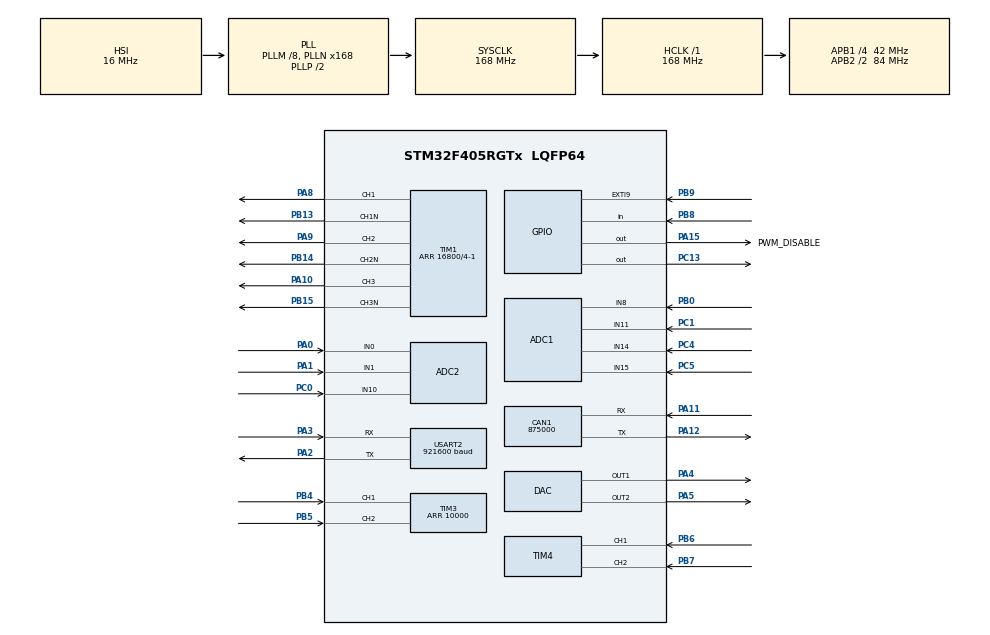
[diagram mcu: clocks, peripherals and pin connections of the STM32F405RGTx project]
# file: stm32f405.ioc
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ADC1.Channel-0\#ChannelRegularConversion=ADC_CHANNEL_14
ADC1.Channel-6\#ChannelInjectedConversion=ADC_CHANNEL_14
ADC1.Channel-7\#ChannelInjectedConversion=ADC_CHANNEL_15
ADC1.Channel-8\#ChannelInjectedConversion=ADC_CHANNEL_8
ADC1.Channel-9\#ChannelInjectedConversion=ADC_CHANNEL_11
ADC1.DMAContinuousRequests=DISABLE
ADC1.ExternalTrigInjecConv=ADC_EXTERNALTRIGINJECCONV_T1_TRGO
ADC1.InjNumberOfConversion=4
ADC1.InjectedOffset-6\#ChannelInjectedConversion=0
ADC1.InjectedOffset-7\#ChannelInjectedConversion=0
ADC1.InjectedOffset-8\#ChannelInjectedConversion=0
ADC1.InjectedOffset-9\#ChannelInjectedConversion=0
ADC1.InjectedRank-6\#ChannelInjectedConversion=1
ADC1.InjectedRank-7\#ChannelInjectedConversion=2
ADC1.InjectedRank-8\#ChannelInjectedConversion=3
ADC1.InjectedRank-9\#ChannelInjectedConversion=4
ADC1.NbrOfConversion=1
ADC1.NbrOfConversionFlag=1
ADC1.Rank-0\#ChannelRegularConversion=1
ADC1.SamplingTime-0\#ChannelRegularConversion=ADC_SAMPLETIME_3CYCLES
ADC1.SamplingTime-6\#ChannelInjectedConversion=ADC_SAMPLETIME_3CYCLES
ADC1.SamplingTime-7\#ChannelInjectedConversion=ADC_SAMPLETIME_3CYCLES
ADC1.SamplingTime-8\#ChannelInjectedConversion=ADC_SAMPLETIME_3CYCLES
ADC1.SamplingTime-9\#ChannelInjectedConversion=ADC_SAMPLETIME_3CYCLES
ADC1.ScanConvMode=ENABLE
ADC1.master=1
ADC2.Channel-0\#ChannelRegularConversion=ADC_CHANNEL_1
ADC2.NbrOfConversionFlag=1
ADC2.Rank-0\#ChannelRegularConversion=1
ADC2.SamplingTime-0\#ChannelRegularConversion=ADC_SAMPLETIME_3CYCLES
CAN1.CalculateBaudRate=875000
CAN1.CalculateTimeBit=1142
CAN1.CalculateTimeQuantum=380.95238095238096
Dma.Request0=USART2_RX
Dma.USART2_RX.0.Direction=DMA_PERIPH_TO_MEMORY
Dma.USART2_RX.0.FIFOMode=DMA_FIFOMODE_DISABLE
Dma.USART2_RX.0.Instance=DMA1_Stream5
Dma.USART2_RX.0.MemDataAlignment=DMA_MDATAALIGN_BYTE
Dma.USART2_RX.0.MemInc=DMA_MINC_ENABLE
Dma.USART2_RX.0.Mode=DMA_CIRCULAR
Dma.USART2_RX.0.PeriphDataAlignment=DMA_PDATAALIGN_BYTE
Dma.USART2_RX.0.PeriphInc=DMA_PINC_DISABLE
Dma.USART2_RX.0.Priority=DMA_PRIORITY_LOW
Mcu.Family=STM32F4
Mcu.Name=STM32F405RGTx
Mcu.Package=LQFP64
NVIC.ADC_IRQn=true\:0\:0\:false\:false\:true\:true\:true\:true
NVIC.DMA1_Stream5_IRQn=true\:0\:0\:false\:false\:true\:false\:true\:true
NVIC.EXTI9_5_IRQn=true\:0\:0\:false\:false\:true\:true\:true\:true
NVIC.PriorityGroup=NVIC_PRIORITYGROUP_4
NVIC.TIM1_BRK_TIM9_IRQn=true\:0\:0\:false\:false\:true\:true\:true\:true
NVIC.TIM8_TRG_COM_TIM14_IRQn=true\:0\:0\:false\:false\:true\:true\:true\:true
NVIC.USART2_IRQn=true\:0\:0\:false\:false\:true\:true\:true\:true
PA0-WKUP.Signal=ADCx_IN0
PA1.Signal=ADCx_IN1
PA10.Signal=S_TIM1_CH3
PA11.Mode=CAN_Activate
PA11.Signal=CAN1_RX
PA12.Mode=CAN_Activate
PA12.Signal=CAN1_TX
PA13.Mode=Serial_Wire
PA13.Signal=SYS_JTMS-SWDIO
PA14.Mode=Serial_Wire
PA14.Signal=SYS_JTCK-SWCLK
PA15.GPIO_Label=PWM_DISABLE
PA15.GPIO_PuPd=GPIO_PULLUP
PA15.Signal=GPIO_Output
PA2.Mode=Asynchronous
PA2.Signal=USART2_TX
PA3.Mode=Asynchronous
PA3.Signal=USART2_RX
PA4.Signal=COMP_DAC1_group
PA5.Signal=COMP_DAC2_group
PA8.Signal=S_TIM1_CH1
PA9.Signal=S_TIM1_CH2
PB0.Signal=ADCx_IN8
PB13.Mode=PWM Generation1 CH1 CH1N
PB13.Signal=TIM1_CH1N
PB14.Mode=PWM Generation2 CH2 CH2N
PB14.Signal=TIM1_CH2N
PB15.Mode=PWM Generation3 CH3 CH3N
PB15.Signal=TIM1_CH3N
PB4.Signal=S_TIM3_CH1
PB5.Signal=S_TIM3_CH2
PB6.Signal=S_TIM4_CH1
PB7.Signal=S_TIM4_CH2
PB8.Signal=GPIO_Input
PB9.Signal=GPXTI9
PC0.Signal=ADCx_IN10
PC1.Signal=ADCx_IN11
PC13-ANTI_TAMP.Signal=GPIO_Output
PC4.Signal=ADCx_IN14
PC5.Signal=ADCx_IN15
PH0-OSC_IN.Mode=HSE-External-Oscillator
PH0-OSC_IN.Signal=RCC_OSC_IN
PH1-OSC_OUT.Mode=HSE-External-Oscillator
PH1-OSC_OUT.Signal=RCC_OSC_OUT
ProjectManager.HeapSize=0x200
ProjectManager.StackSize=0x400
ProjectManager.TargetToolchain=MDK-ARM V5.32
RCC.48MHZClocksFreq_Value=84000000
RCC.AHBFreq_Value=168000000
RCC.APB1CLKDivider=RCC_HCLK_DIV4
RCC.APB1Freq_Value=42000000
RCC.APB1TimFreq_Value=84000000
RCC.APB2CLKDivider=RCC_HCLK_DIV2
RCC.APB2Freq_Value=84000000
RCC.APB2TimFreq_Value=168000000
RCC.CortexFreq_Value=168000000
RCC.HCLKFreq_Value=168000000
RCC.HSE_VALUE=8000000
RCC.HSI_VALUE=16000000
RCC.LSE_VALUE=32768
RCC.PLLM=8
RCC.PLLN=168
RCC.SYSCLKFreq_VALUE=168000000
RCC.SYSCLKSource=RCC_SYSCLKSOURCE_PLLCLK
RCC.VCOOutputFreq_Value=336000000
SH.ADCx_IN0.0=ADC2_IN0,IN0
SH.ADCx_IN1.0=ADC2_IN1,IN1
SH.ADCx_IN10.0=ADC2_IN10,IN10
SH.ADCx_IN11.0=ADC1_IN11,IN11
SH.ADCx_IN14.0=ADC1_IN14,IN14
SH.ADCx_IN15.0=ADC1_IN15,IN15
SH.ADCx_IN8.0=ADC1_IN8,IN8
SH.COMP_DAC1_group.0=DAC_OUT1,DAC_OUT1
SH.COMP_DAC2_group.0=DAC_OUT2,DAC_OUT2
SH.S_TIM1_CH1.0=TIM1_CH1,PWM Generation1 CH1 CH1N
SH.S_TIM1_CH2.0=TIM1_CH2,PWM Generation2 CH2 CH2N
SH.S_TIM1_CH3.0=TIM1_CH3,PWM Generation3 CH3 CH3N
SH.S_TIM3_CH1.0=TIM3_CH1,Encoder_Interface
SH.S_TIM3_CH2.0=TIM3_CH2,Encoder_Interface
SH.S_TIM4_CH1.0=TIM4_CH1,Encoder_Interface
SH.S_TIM4_CH2.0=TIM4_CH2,Encoder_Interface
TIM1.Channel-PWM\ Generation1\ CH1\ CH1N=TIM_CHANNEL_1
TIM1.Channel-PWM\ Generation2\ CH2\ CH2N=TIM_CHANNEL_2
TIM1.Channel-PWM\ Generation3\ CH3\ CH3N=TIM_CHANNEL_3
TIM1.Channel-PWM\ Generation4\ No\ Output=TIM_CHANNEL_4
TIM1.CounterMode=TIM_COUNTERMODE_CENTERALIGNED1
TIM1.DeadTime=100
TIM1.OCMode_PWM-PWM\ Generation1\ CH1\ CH1N=TIM_OCMODE_PWM1
TIM1.OCMode_PWM-PWM\ Generation2\ CH2\ CH2N=TIM_OCMODE_PWM1
TIM1.OCMode_PWM-PWM\ Generation3\ CH3\ CH3N=TIM_OCMODE_PWM1
TIM1.OCMode_PWM-PWM\ Generation4\ No\ Output=TIM_OCMODE_PWM2
TIM1.OCNPolarity_1=TIM_OCNPOLARITY_LOW
TIM1.OCNPolarity_2=TIM_OCNPOLARITY_LOW
TIM1.OCNPolarity_3=TIM_OCNPOLARITY_LOW
TIM1.OCPolarity_1=TIM_OCPOLARITY_LOW
TIM1.OCPolarity_2=TIM_OCPOLARITY_LOW
TIM1.OCPolarity_3=TIM_OCPOLARITY_LOW
TIM1.Period=16800/4-1
TIM1.Pulse-PWM\ Generation4\ No\ Output=16800/2-2
TIM1.RepetitionCounter=1
TIM1.TIM_MasterOutputTrigger=TIM_TRGO_OC4REF
TIM3.EncoderMode=TIM_ENCODERMODE_TI12
TIM3.Period=10000
USART2.BaudRate=921600
USART2.VirtualMode=VM_ASYNC
VP_TIM14_VS_ClockSourceINT.Mode=Enable_Timer
VP_TIM1_VS_ClockSourceINT.Mode=Internal
VP_TIM1_VS_no_output4.Mode=PWM Generation4 No Output
board=custom

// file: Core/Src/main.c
/* USER CODE BEGIN Header */
/**
  ******************************************************************************
  * @file           : main.c
  * @brief          : Main program body
  ******************************************************************************
  * @attention
  *
  * Copyright (c) 2026 STMicroelectronics.
  * All rights reserved.
  *
  * This software is licensed under terms that can be found in the LICENSE file
  * in the root directory of this software component.
  * If no LICENSE file comes with this software, it is provided AS-IS.
  *
  ******************************************************************************
  */
/* USER CODE END Header */
#include "main.h"

/* USER CODE BEGIN Includes */
#include <gmp_core.h>
/* USER CODE END Includes */

ADC_HandleTypeDef hadc1;
ADC_HandleTypeDef hadc2;

CAN_HandleTypeDef hcan1;

DAC_HandleTypeDef hdac;

TIM_HandleTypeDef htim1;
TIM_HandleTypeDef htim3;
TIM_HandleTypeDef htim4;
TIM_HandleTypeDef htim14;

UART_HandleTypeDef huart2;
DMA_HandleTypeDef hdma_usart2_rx;

void SystemClock_Config(void);
static void MX_GPIO_Init(void);
static void MX_DMA_Init(void);
static void MX_ADC1_Init(void);
static void MX_TIM1_Init(void);
static void MX_ADC2_Init(void);
static void MX_TIM3_Init(void);
static void MX_TIM4_Init(void);
static void MX_USART2_UART_Init(void);
static void MX_TIM14_Init(void);
static void MX_DAC_Init(void);
static void MX_CAN1_Init(void);

int main(void)
{

  /* MCU Configuration--------------------------------------------------------*/

  /* Reset of all peripherals, Initializes the Flash interface and the Systick. */
  HAL_Init();

  /* Configure the system clock */
  SystemClock_Config();

  /* Initialize all configured peripherals */
  MX_GPIO_Init();
  MX_DMA_Init();
  MX_ADC1_Init();
  MX_TIM1_Init();
  MX_ADC2_Init();
  MX_TIM3_Init();
  MX_TIM4_Init();
  MX_USART2_UART_Init();
  MX_TIM14_Init();
  MX_DAC_Init();
  MX_CAN1_Init();
  /* USER CODE BEGIN 2 */
	gmp_base_entry();
  /* USER CODE END 2 */

  /* Infinite loop */
  while (1)
  {

  }
}

void SystemClock_Config(void)
{
  RCC_OscInitTypeDef RCC_OscInitStruct = {0};
  RCC_ClkInitTypeDef RCC_ClkInitStruct = {0};

  /** Configure the main internal regulator output voltage
  */
  __HAL_RCC_PWR_CLK_ENABLE();
  __HAL_PWR_VOLTAGESCALING_CONFIG(PWR_REGULATOR_VOLTAGE_SCALE1);

  /** Initializes the RCC Oscillators according to the specified parameters
  * in the RCC_OscInitTypeDef structure.
  */
  RCC_OscInitStruct.OscillatorType = RCC_OSCILLATORTYPE_HSI;
  RCC_OscInitStruct.HSIState = RCC_HSI_ON;
  RCC_OscInitStruct.HSICalibrationValue = RCC_HSICALIBRATION_DEFAULT;
  RCC_OscInitStruct.PLL.PLLState = RCC_PLL_ON;
  RCC_OscInitStruct.PLL.PLLSource = RCC_PLLSOURCE_HSI;
  RCC_OscInitStruct.PLL.PLLM = 8;
  RCC_OscInitStruct.PLL.PLLN = 168;
  RCC_OscInitStruct.PLL.PLLP = RCC_PLLP_DIV2;
  RCC_OscInitStruct.PLL.PLLQ = 4;
  if (HAL_RCC_OscConfig(&RCC_OscInitStruct) != HAL_OK)
  {
    Error_Handler();
  }

  /** Initializes the CPU, AHB and APB buses clocks
  */
  RCC_ClkInitStruct.ClockType = RCC_CLOCKTYPE_HCLK|RCC_CLOCKTYPE_SYSCLK
                              |RCC_CLOCKTYPE_PCLK1|RCC_CLOCKTYPE_PCLK2;
  RCC_ClkInitStruct.SYSCLKSource = RCC_SYSCLKSOURCE_PLLCLK;
  RCC_ClkInitStruct.AHBCLKDivider = RCC_SYSCLK_DIV1;
  RCC_ClkInitStruct.APB1CLKDivider = RCC_HCLK_DIV4;
  RCC_ClkInitStruct.APB2CLKDivider = RCC_HCLK_DIV2;

  if (HAL_RCC_ClockConfig(&RCC_ClkInitStruct, FLASH_LATENCY_5) != HAL_OK)
  {
    Error_Handler();
  }
}

static void MX_ADC1_Init(void)
{

  ADC_ChannelConfTypeDef sConfig = {0};
  ADC_InjectionConfTypeDef sConfigInjected = {0};

  /** Configure the global features of the ADC (Clock, Resolution, Data Alignment and number of conversion)
  */
  hadc1.Instance = ADC1;
  hadc1.Init.ClockPrescaler = ADC_CLOCK_SYNC_PCLK_DIV4;
  hadc1.Init.Resolution = ADC_RESOLUTION_12B;
  hadc1.Init.ScanConvMode = ENABLE;
  hadc1.Init.ContinuousConvMode = DISABLE;
  hadc1.Init.DiscontinuousConvMode = DISABLE;
  hadc1.Init.ExternalTrigConvEdge = ADC_EXTERNALTRIGCONVEDGE_NONE;
  hadc1.Init.ExternalTrigConv = ADC_SOFTWARE_START;
  hadc1.Init.DataAlign = ADC_DATAALIGN_RIGHT;
  hadc1.Init.NbrOfConversion = 1;
  hadc1.Init.DMAContinuousRequests = DISABLE;
  hadc1.Init.EOCSelection = ADC_EOC_SINGLE_CONV;
  if (HAL_ADC_Init(&hadc1) != HAL_OK)
  {
    Error_Handler();
  }

  /** Configure for the selected ADC regular channel its corresponding rank in the sequencer and its sample time.
  */
  sConfig.Channel = ADC_CHANNEL_14;
  sConfig.Rank = 1;
  sConfig.SamplingTime = ADC_SAMPLETIME_3CYCLES;
  if (HAL_ADC_ConfigChannel(&hadc1, &sConfig) != HAL_OK)
  {
    Error_Handler();
  }

  /** Configures for the selected ADC injected channel its corresponding rank in the sequencer and its sample time
  */
  sConfigInjected.InjectedChannel = ADC_CHANNEL_14;
  sConfigInjected.InjectedRank = 1;
  sConfigInjected.InjectedNbrOfConversion = 4;
  sConfigInjected.InjectedSamplingTime = ADC_SAMPLETIME_3CYCLES;
  sConfigInjected.ExternalTrigInjecConvEdge = ADC_EXTERNALTRIGINJECCONVEDGE_RISING;
  sConfigInjected.ExternalTrigInjecConv = ADC_EXTERNALTRIGINJECCONV_T1_TRGO;
  sConfigInjected.AutoInjectedConv = DISABLE;
  sConfigInjected.InjectedDiscontinuousConvMode = DISABLE;
  sConfigInjected.InjectedOffset = 0;
  if (HAL_ADCEx_InjectedConfigChannel(&hadc1, &sConfigInjected) != HAL_OK)
  {
    Error_Handler();
  }

  /** Configures for the selected ADC injected channel its corresponding rank in the sequencer and its sample time
  */
  sConfigInjected.InjectedChannel = ADC_CHANNEL_15;
  sConfigInjected.InjectedRank = 2;
  if (HAL_ADCEx_InjectedConfigChannel(&hadc1, &sConfigInjected) != HAL_OK)
  {
    Error_Handler();
  }

  /** Configures for the selected ADC injected channel its corresponding rank in the sequencer and its sample time
  */
  sConfigInjected.InjectedChannel = ADC_CHANNEL_8;
  sConfigInjected.InjectedRank = 3;
  if (HAL_ADCEx_InjectedConfigChannel(&hadc1, &sConfigInjected) != HAL_OK)
  {
    Error_Handler();
  }

  /** Configures for the selected ADC injected channel its corresponding rank in the sequencer and its sample time
  */
  sConfigInjected.InjectedChannel = ADC_CHANNEL_11;
  sConfigInjected.InjectedRank = 4;
  if (HAL_ADCEx_InjectedConfigChannel(&hadc1, &sConfigInjected) != HAL_OK)
  {
    Error_Handler();
  }

}

static void MX_ADC2_Init(void)
{

  ADC_ChannelConfTypeDef sConfig = {0};

  /** Configure the global features of the ADC (Clock, Resolution, Data Alignment and number of conversion)
  */
  hadc2.Instance = ADC2;
  hadc2.Init.ClockPrescaler = ADC_CLOCK_SYNC_PCLK_DIV4;
  hadc2.Init.Resolution = ADC_RESOLUTION_12B;
  hadc2.Init.ScanConvMode = DISABLE;
  hadc2.Init.ContinuousConvMode = DISABLE;
  hadc2.Init.DiscontinuousConvMode = DISABLE;
  hadc2.Init.ExternalTrigConvEdge = ADC_EXTERNALTRIGCONVEDGE_NONE;
  hadc2.Init.ExternalTrigConv = ADC_SOFTWARE_START;
  hadc2.Init.DataAlign = ADC_DATAALIGN_RIGHT;
  hadc2.Init.NbrOfConversion = 1;
  hadc2.Init.DMAContinuousRequests = DISABLE;
  hadc2.Init.EOCSelection = ADC_EOC_SINGLE_CONV;
  if (HAL_ADC_Init(&hadc2) != HAL_OK)
  {
    Error_Handler();
  }

  /** Configure for the selected ADC regular channel its corresponding rank in the sequencer and its sample time.
  */
  sConfig.Channel = ADC_CHANNEL_1;
  sConfig.Rank = 1;
  sConfig.SamplingTime = ADC_SAMPLETIME_3CYCLES;
  if (HAL_ADC_ConfigChannel(&hadc2, &sConfig) != HAL_OK)
  {
    Error_Handler();
  }

}

static void MX_CAN1_Init(void)
{

  hcan1.Instance = CAN1;
  hcan1.Init.Prescaler = 16;
  hcan1.Init.Mode = CAN_MODE_NORMAL;
  hcan1.Init.SyncJumpWidth = CAN_SJW_1TQ;
  hcan1.Init.TimeSeg1 = CAN_BS1_1TQ;
  hcan1.Init.TimeSeg2 = CAN_BS2_1TQ;
  hcan1.Init.TimeTriggeredMode = DISABLE;
  hcan1.Init.AutoBusOff = DISABLE;
  hcan1.Init.AutoWakeUp = DISABLE;
  hcan1.Init.AutoRetransmission = DISABLE;
  hcan1.Init.ReceiveFifoLocked = DISABLE;
  hcan1.Init.TransmitFifoPriority = DISABLE;
  if (HAL_CAN_Init(&hcan1) != HAL_OK)
  {
    Error_Handler();
  }

}

static void MX_DAC_Init(void)
{

  DAC_ChannelConfTypeDef sConfig = {0};

  /** DAC Initialization
  */
  hdac.Instance = DAC;
  if (HAL_DAC_Init(&hdac) != HAL_OK)
  {
    Error_Handler();
  }

  /** DAC channel OUT1 config
  */
  sConfig.DAC_Trigger = DAC_TRIGGER_NONE;
  sConfig.DAC_OutputBuffer = DAC_OUTPUTBUFFER_ENABLE;
  if (HAL_DAC_ConfigChannel(&hdac, &sConfig, DAC_CHANNEL_1) != HAL_OK)
  {
    Error_Handler();
  }

  /** DAC channel OUT2 config
  */
  if (HAL_DAC_ConfigChannel(&hdac, &sConfig, DAC_CHANNEL_2) != HAL_OK)
  {
    Error_Handler();
  }

}

static void MX_TIM1_Init(void)
{

  TIM_ClockConfigTypeDef sClockSourceConfig = {0};
  TIM_MasterConfigTypeDef sMasterConfig = {0};
  TIM_OC_InitTypeDef sConfigOC = {0};
  TIM_BreakDeadTimeConfigTypeDef sBreakDeadTimeConfig = {0};

  htim1.Instance = TIM1;
  htim1.Init.Prescaler = 0;
  htim1.Init.CounterMode = TIM_COUNTERMODE_CENTERALIGNED1;
  htim1.Init.Period = 16800/4-1;
  htim1.Init.ClockDivision = TIM_CLOCKDIVISION_DIV1;
  htim1.Init.RepetitionCounter = 1;
  htim1.Init.AutoReloadPreload = TIM_AUTORELOAD_PRELOAD_DISABLE;
  if (HAL_TIM_Base_Init(&htim1) != HAL_OK)
  {
    Error_Handler();
  }
  sClockSourceConfig.ClockSource = TIM_CLOCKSOURCE_INTERNAL;
  if (HAL_TIM_ConfigClockSource(&htim1, &sClockSourceConfig) != HAL_OK)
  {
    Error_Handler();
  }
  if (HAL_TIM_PWM_Init(&htim1) != HAL_OK)
  {
    Error_Handler();
  }
  sMasterConfig.MasterOutputTrigger = TIM_TRGO_OC4REF;
  sMasterConfig.MasterSlaveMode = TIM_MASTERSLAVEMODE_DISABLE;
  if (HAL_TIMEx_MasterConfigSynchronization(&htim1, &sMasterConfig) != HAL_OK)
  {
    Error_Handler();
  }
  sConfigOC.OCMode = TIM_OCMODE_PWM1;
  sConfigOC.Pulse = 0;
  sConfigOC.OCPolarity = TIM_OCPOLARITY_LOW;
  sConfigOC.OCNPolarity = TIM_OCNPOLARITY_LOW;
  sConfigOC.OCFastMode = TIM_OCFAST_DISABLE;
  sConfigOC.OCIdleState = TIM_OCIDLESTATE_RESET;
  sConfigOC.OCNIdleState = TIM_OCNIDLESTATE_RESET;
  if (HAL_TIM_PWM_ConfigChannel(&htim1, &sConfigOC, TIM_CHANNEL_1) != HAL_OK)
  {
    Error_Handler();
  }
  if (HAL_TIM_PWM_ConfigChannel(&htim1, &sConfigOC, TIM_CHANNEL_2) != HAL_OK)
  {
    Error_Handler();
  }
  if (HAL_TIM_PWM_ConfigChannel(&htim1, &sConfigOC, TIM_CHANNEL_3) != HAL_OK)
  {
    Error_Handler();
  }
  sConfigOC.OCMode = TIM_OCMODE_PWM2;
  sConfigOC.Pulse = 16800/2-2;
  sConfigOC.OCPolarity = TIM_OCPOLARITY_HIGH;
  if (HAL_TIM_PWM_ConfigChannel(&htim1, &sConfigOC, TIM_CHANNEL_4) != HAL_OK)
  {
    Error_Handler();
  }
  sBreakDeadTimeConfig.OffStateRunMode = TIM_OSSR_DISABLE;
  sBreakDeadTimeConfig.OffStateIDLEMode = TIM_OSSI_DISABLE;
  sBreakDeadTimeConfig.LockLevel = TIM_LOCKLEVEL_OFF;
  sBreakDeadTimeConfig.DeadTime = 100;
  sBreakDeadTimeConfig.BreakState = TIM_BREAK_DISABLE;
  sBreakDeadTimeConfig.BreakPolarity = TIM_BREAKPOLARITY_HIGH;
  sBreakDeadTimeConfig.AutomaticOutput = TIM_AUTOMATICOUTPUT_DISABLE;
  if (HAL_TIMEx_ConfigBreakDeadTime(&htim1, &sBreakDeadTimeConfig) != HAL_OK)
  {
    Error_Handler();
  }
  HAL_TIM_MspPostInit(&htim1);

}

static void MX_TIM3_Init(void)
{

  TIM_Encoder_InitTypeDef sConfig = {0};
  TIM_MasterConfigTypeDef sMasterConfig = {0};

  htim3.Instance = TIM3;
  htim3.Init.Prescaler = 0;
  htim3.Init.CounterMode = TIM_COUNTERMODE_UP;
  htim3.Init.Period = 10000;
  htim3.Init.ClockDivision = TIM_CLOCKDIVISION_DIV1;
  htim3.Init.AutoReloadPreload = TIM_AUTORELOAD_PRELOAD_DISABLE;
  sConfig.EncoderMode = TIM_ENCODERMODE_TI12;
  sConfig.IC1Polarity = TIM_ICPOLARITY_RISING;
  sConfig.IC1Selection = TIM_ICSELECTION_DIRECTTI;
  sConfig.IC1Prescaler = TIM_ICPSC_DIV1;
  sConfig.IC1Filter = 0;
  sConfig.IC2Polarity = TIM_ICPOLARITY_RISING;
  sConfig.IC2Selection = TIM_ICSELECTION_DIRECTTI;
  sConfig.IC2Prescaler = TIM_ICPSC_DIV1;
  sConfig.IC2Filter = 0;
  if (HAL_TIM_Encoder_Init(&htim3, &sConfig) != HAL_OK)
  {
    Error_Handler();
  }
  sMasterConfig.MasterOutputTrigger = TIM_TRGO_RESET;
  sMasterConfig.MasterSlaveMode = TIM_MASTERSLAVEMODE_DISABLE;
  if (HAL_TIMEx_MasterConfigSynchronization(&htim3, &sMasterConfig) != HAL_OK)
  {
    Error_Handler();
  }

}

static void MX_TIM4_Init(void)
{

  TIM_Encoder_InitTypeDef sConfig = {0};
  TIM_MasterConfigTypeDef sMasterConfig = {0};

  htim4.Instance = TIM4;
  htim4.Init.Prescaler = 0;
  htim4.Init.CounterMode = TIM_COUNTERMODE_UP;
  htim4.Init.Period = 65535;
  htim4.Init.ClockDivision = TIM_CLOCKDIVISION_DIV1;
  htim4.Init.AutoReloadPreload = TIM_AUTORELOAD_PRELOAD_DISABLE;
  sConfig.EncoderMode = TIM_ENCODERMODE_TI1;
  sConfig.IC1Polarity = TIM_ICPOLARITY_RISING;
  sConfig.IC1Selection = TIM_ICSELECTION_DIRECTTI;
  sConfig.IC1Prescaler = TIM_ICPSC_DIV1;
  sConfig.IC1Filter = 0;
  sConfig.IC2Polarity = TIM_ICPOLARITY_RISING;
  sConfig.IC2Selection = TIM_ICSELECTION_DIRECTTI;
  sConfig.IC2Prescaler = TIM_ICPSC_DIV1;
  sConfig.IC2Filter = 0;
  if (HAL_TIM_Encoder_Init(&htim4, &sConfig) != HAL_OK)
  {
    Error_Handler();
  }
  sMasterConfig.MasterOutputTrigger = TIM_TRGO_RESET;
  sMasterConfig.MasterSlaveMode = TIM_MASTERSLAVEMODE_DISABLE;
  if (HAL_TIMEx_MasterConfigSynchronization(&htim4, &sMasterConfig) != HAL_OK)
  {
    Error_Handler();
  }

}

static void MX_TIM14_Init(void)
{

  htim14.Instance = TIM14;
  htim14.Init.Prescaler = 0;
  htim14.Init.CounterMode = TIM_COUNTERMODE_UP;
  htim14.Init.Period = 65535;
  htim14.Init.ClockDivision = TIM_CLOCKDIVISION_DIV1;
  htim14.Init.AutoReloadPreload = TIM_AUTORELOAD_PRELOAD_DISABLE;
  if (HAL_TIM_Base_Init(&htim14) != HAL_OK)
  {
    Error_Handler();
  }

}

static void MX_USART2_UART_Init(void)
{

  huart2.Instance = USART2;
  huart2.Init.BaudRate = 921600;
  huart2.Init.WordLength = UART_WORDLENGTH_8B;
  huart2.Init.StopBits = UART_STOPBITS_1;
  huart2.Init.Parity = UART_PARITY_NONE;
  huart2.Init.Mode = UART_MODE_TX_RX;
  huart2.Init.HwFlowCtl = UART_HWCONTROL_NONE;
  huart2.Init.OverSampling = UART_OVERSAMPLING_16;
  if (HAL_UART_Init(&huart2) != HAL_OK)
  {
    Error_Handler();
  }

}

static void MX_DMA_Init(void)
{

  /* DMA controller clock enable */
  __HAL_RCC_DMA1_CLK_ENABLE();

  /* DMA interrupt init */
  /* DMA1_Stream5_IRQn interrupt configuration */
  HAL_NVIC_SetPriority(DMA1_Stream5_IRQn, 0, 0);
  HAL_NVIC_EnableIRQ(DMA1_Stream5_IRQn);

}

static void MX_GPIO_Init(void)
{
  GPIO_InitTypeDef GPIO_InitStruct = {0};

  /* GPIO Ports Clock Enable */
  __HAL_RCC_GPIOC_CLK_ENABLE();
  __HAL_RCC_GPIOH_CLK_ENABLE();
  __HAL_RCC_GPIOA_CLK_ENABLE();
  __HAL_RCC_GPIOB_CLK_ENABLE();

  /*Configure GPIO pin Output Level */
  HAL_GPIO_WritePin(GPIOC, GPIO_PIN_13, GPIO_PIN_RESET);

  /*Configure GPIO pin Output Level */
  HAL_GPIO_WritePin(PWM_DISABLE_GPIO_Port, PWM_DISABLE_Pin, GPIO_PIN_RESET);

  /*Configure GPIO pin : PC13 */
  GPIO_InitStruct.Pin = GPIO_PIN_13;
  GPIO_InitStruct.Mode = GPIO_MODE_OUTPUT_PP;
  GPIO_InitStruct.Pull = GPIO_NOPULL;
  GPIO_InitStruct.Speed = GPIO_SPEED_FREQ_LOW;
  HAL_GPIO_Init(GPIOC, &GPIO_InitStruct);

  /*Configure GPIO pin : PWM_DISABLE_Pin */
  GPIO_InitStruct.Pin = PWM_DISABLE_Pin;
  GPIO_InitStruct.Mode = GPIO_MODE_OUTPUT_PP;
  GPIO_InitStruct.Pull = GPIO_PULLUP;
  GPIO_InitStruct.Speed = GPIO_SPEED_FREQ_LOW;
  HAL_GPIO_Init(PWM_DISABLE_GPIO_Port, &GPIO_InitStruct);

  /*Configure GPIO pin : PB8 */
  GPIO_InitStruct.Pin = GPIO_PIN_8;
  GPIO_InitStruct.Mode = GPIO_MODE_INPUT;
  GPIO_InitStruct.Pull = GPIO_NOPULL;
  HAL_GPIO_Init(GPIOB, &GPIO_InitStruct);

  /*Configure GPIO pin : PB9 */
  GPIO_InitStruct.Pin = GPIO_PIN_9;
  GPIO_InitStruct.Mode = GPIO_MODE_IT_RISING;
  GPIO_InitStruct.Pull = GPIO_NOPULL;
  HAL_GPIO_Init(GPIOB, &GPIO_InitStruct);

  /* EXTI interrupt init*/
  HAL_NVIC_SetPriority(EXTI9_5_IRQn, 0, 0);
  HAL_NVIC_EnableIRQ(EXTI9_5_IRQn);

}

void Error_Handler(void)
{
  __disable_irq();
  while (1)
  {
  }
}
